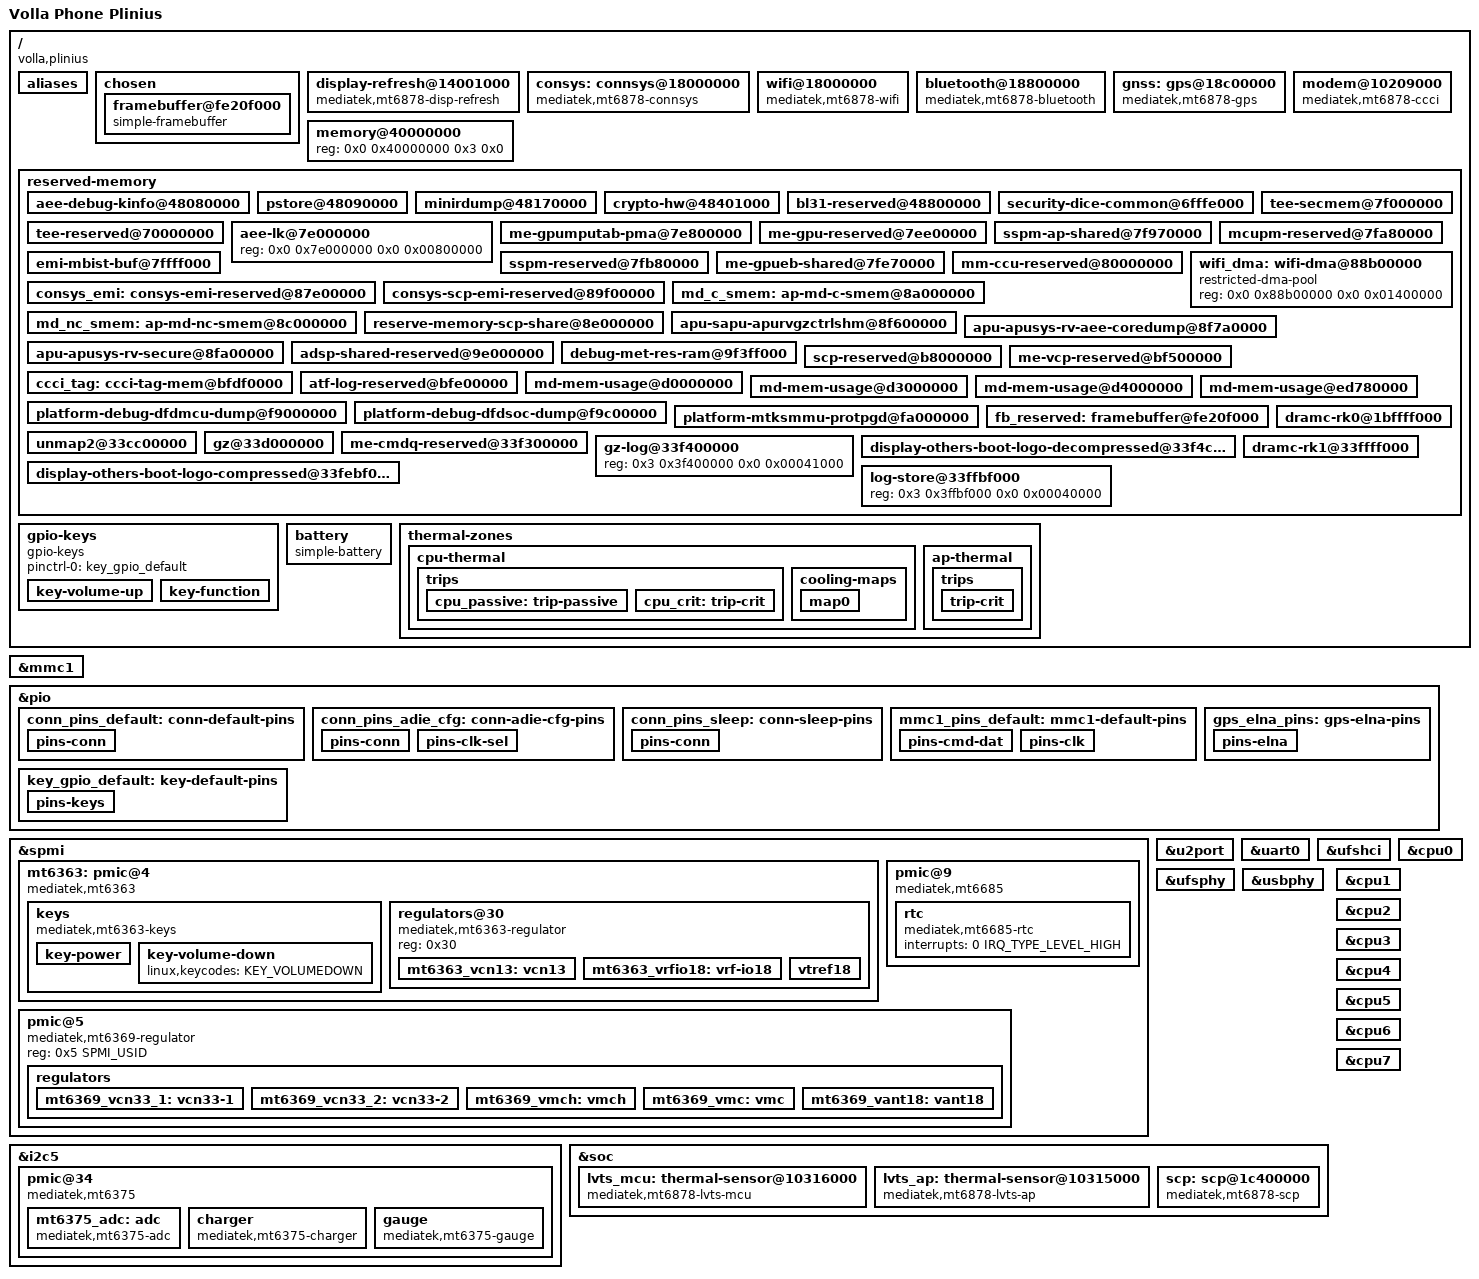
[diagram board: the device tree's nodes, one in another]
// SPDX-License-Identifier: GPL-2.0 OR MIT
/*
 * Volla Phone Plinius (ansuz)
 */

/dts-v1/;
#include "mt6878.dtsi"
#include <dt-bindings/gpio/gpio.h>
#include <dt-bindings/iio/adc/mediatek,mt6375_adc.h>
#include <dt-bindings/input/input.h>
#include <dt-bindings/interrupt-controller/irq.h>
#include <dt-bindings/mfd/mt6375.h>
#include <dt-bindings/pinctrl/mt65xx.h>
#include <dt-bindings/power/mediatek,mt6878-power.h>
#include <dt-bindings/spmi/spmi.h>
#include <dt-bindings/thermal/mediatek,lvts-thermal.h>
#include <dt-bindings/thermal/thermal.h>

/*
 * The SoC dtsi carries the CMF Phone 1 carveouts, Plinius gets its own
 * set taken from what the stock LK hands to the kernel.
 */
/delete-node/ &{/reserved-memory};

/ {
	model = "Volla Phone Plinius";
	chassis-type = "handset";
	compatible = "volla,plinius", "mediatek,mt6878";

	#address-cells = <2>;
	#size-cells = <2>;

	aliases {
		mmc1 = &mmc1;
		serial0 = &uart0;
	};

	chosen {
		bootargs = "clk_ignore_unused";
		stdout-path = "serial0:921600n8";
		#address-cells = <2>;
		#size-cells = <2>;
		ranges;

		/* Left set up by the stock LK */
		framebuffer@fe20f000 {
			compatible = "simple-framebuffer";
			reg = <0x0 0xfe20f000 0x0 0xa08c00>;
			memory-region = <&fb_reserved>;
			width = <1080>;
			height = <2400>;
			stride = <(1088 * 4)>;
			format = "a8r8g8b8";
		};
	};

	/*
	 * The LK leaves OVL0 -> ... -> DSI0 scanning out the framebuffer
	 * above to the command mode panel; keep pushing frames to it.
	 */
	display-refresh@14001000 {
		compatible = "mediatek,mt6878-disp-refresh";
		reg = <0x0 0x14001000 0x0 0x1000>,
		      <0x0 0x1401a000 0x0 0x1000>;
		reg-names = "mutex", "dsi";
		mediatek,mutex-id = <0>;
	};

	/* Connectivity subsystem (WiFi/BT/GPS) with the MT6637 A-die */
	consys: connsys@18000000 {
		compatible = "mediatek,mt6878-connsys";
		reg = <0x0 0x18000000 0x0 0x80000>,
		      <0x0 0x1c00d000 0x0 0x1000>;
		reg-names = "conn", "srclken-rc";
		memory-region = <&consys_emi>;
		power-domains = <&spm MT6878_POWER_DOMAIN_CONN>;
		mediatek,topckgen = <&topckgen>;
		pinctrl-names = "default", "sleep", "adie-cfg";
		pinctrl-0 = <&conn_pins_default>;
		pinctrl-1 = <&conn_pins_sleep>;
		pinctrl-2 = <&conn_pins_adie_cfg>;
		vrfio18-supply = <&mt6363_vrfio18>;
		vcn13-supply = <&mt6363_vcn13>;
		vcn33-1-supply = <&mt6369_vcn33_1>;
		vcn33-2-supply = <&mt6369_vcn33_2>;
		vant18-supply = <&mt6369_vant18>;
	};

	wifi@18000000 {
		compatible = "mediatek,mt6878-wifi";
		reg = <0x0 0x18000000 0x0 0x700000>;
		interrupts = <GIC_SPI 484 IRQ_TYPE_LEVEL_HIGH 0>,
			     <GIC_SPI 692 IRQ_TYPE_LEVEL_HIGH 0>;
		memory-region = <&wifi_dma>;
		mediatek,connsys = <&consys>;
	};

	bluetooth@18800000 {
		compatible = "mediatek,mt6878-bluetooth";
		reg = <0x0 0x18000000 0x0 0x61000>,
		      <0x0 0x18800000 0x0 0x21000>;
		reg-names = "conn", "bgf";
		interrupts = <GIC_SPI 693 IRQ_TYPE_LEVEL_HIGH 0>;
		mediatek,connsys = <&consys>;
		/* Factory BD address 58:9E:C6:AB:A6:1A (little-endian here) */
		local-bd-address = [1a a6 ab c6 9e 58];
	};

	gnss: gps@18c00000 {
		compatible = "mediatek,mt6878-gps";
		reg = <0x0 0x18c00000 0x0 0x100000>,
		      <0x0 0x18000000 0x0 0x100000>;
		reg-names = "conn_gps", "conn_infra";
		/* link0 data, link0 nodata, link0 mcub, link1 data,
		 * link1 nodata, link1 mcub, dma (index order matters)
		 */
		interrupts = <GIC_SPI 379 IRQ_TYPE_LEVEL_HIGH 0>,
			     <GIC_SPI 380 IRQ_TYPE_LEVEL_HIGH 0>,
			     <GIC_SPI 381 IRQ_TYPE_LEVEL_HIGH 0>,
			     <GIC_SPI 382 IRQ_TYPE_LEVEL_HIGH 0>,
			     <GIC_SPI 383 IRQ_TYPE_LEVEL_HIGH 0>,
			     <GIC_SPI 389 IRQ_TYPE_LEVEL_HIGH 0>,
			     <GIC_SPI 129 IRQ_TYPE_LEVEL_HIGH 0>;
		mediatek,connsys = <&consys>;
		/*
		 * GPIO186/187 = external GPS L1/L5 eLNA enable. Stock drives them
		 * from its "gps_l1_lna_enable"/"gps_l5_lna_enable" pinctrl states;
		 * mainline left them unclaimed so the eLNAs stayed off and the DSP
		 * saw few/no satellites. Claim them as GPIO outputs driven high for
		 * the whole time the GPS device is bound.
		 */
		pinctrl-names = "default";
		pinctrl-0 = <&gps_elna_pins>;
	};

	modem@10209000 {
		compatible = "mediatek,mt6878-ccci";
		reg = <0x0 0x10209000 0x0 0x1000>,
		      <0x0 0x1020a000 0x0 0x1000>,
		      <0x0 0x1020e000 0x0 0x1000>,
		      <0x0 0x1c001000 0x0 0x1000>,
		      <0x0 0x10000000 0x0 0x1000>,
		      <0x0 0x10001000 0x0 0x1000>,
		      <0x0 0x10270000 0x0 0x1000>,
		      <0x0 0x10014000 0x0 0x1000>,
		      <0x0 0x1022d000 0x0 0x1000>;
		reg-names = "ap-ccif", "md-ccif", "infracfg", "spm", "topckgen",
			    "infracfg-ao", "nemicfg", "dpmaif-ao", "dpmaif-pd";
		interrupts = <GIC_SPI 228 IRQ_TYPE_LEVEL_HIGH 0>,
			     <GIC_SPI 229 IRQ_TYPE_LEVEL_HIGH 0>,
			     <GIC_SPI 238 IRQ_TYPE_LEVEL_HIGH 0>;
		memory-region = <&ccci_tag>, <&md_nc_smem>, <&md_c_smem>;
	};

	memory@40000000 {
		device_type = "memory";
		reg = <0x0 0x40000000 0x3 0x0>;
	};

	reserved-memory {
		#address-cells = <2>;
		#size-cells = <2>;
		ranges;

		aee-debug-kinfo@48080000 {
			reg = <0x0 0x48080000 0x0 0x00010000>;
			no-map;
		};

		pstore@48090000 {
			reg = <0x0 0x48090000 0x0 0x000e0000>;
			no-map;
		};

		minirdump@48170000 {
			reg = <0x0 0x48170000 0x0 0x00010000>;
			no-map;
		};

		crypto-hw@48401000 {
			reg = <0x0 0x48401000 0x0 0x00001000>;
			no-map;
		};

		bl31-reserved@48800000 {
			reg = <0x0 0x48800000 0x0 0x00200000>;
			no-map;
		};

		security-dice-common@6fffe000 {
			reg = <0x0 0x6fffe000 0x0 0x00001000>;
			no-map;
		};

		tee-reserved@70000000 {
			reg = <0x0 0x70000000 0x0 0x06c00000>;
			no-map;
		};

		aee-lk@7e000000 {
			reg = <0x0 0x7e000000 0x0 0x00800000>;
		};

		me-gpumputab-pma@7e800000 {
			reg = <0x0 0x7e800000 0x0 0x00600000>;
			no-map;
		};

		me-gpu-reserved@7ee00000 {
			reg = <0x0 0x7ee00000 0x0 0x00200000>;
			no-map;
		};

		tee-secmem@7f000000 {
			reg = <0x0 0x7f000000 0x0 0x00900000>;
			no-map;
		};

		sspm-ap-shared@7f970000 {
			reg = <0x0 0x7f970000 0x0 0x00110000>;
			no-map;
		};

		mcupm-reserved@7fa80000 {
			reg = <0x0 0x7fa80000 0x0 0x00100000>;
			no-map;
		};

		sspm-reserved@7fb80000 {
			reg = <0x0 0x7fb80000 0x0 0x00280000>;
			no-map;
		};

		me-gpueb-shared@7fe70000 {
			reg = <0x0 0x7fe70000 0x0 0x00180000>;
			no-map;
		};

		emi-mbist-buf@7ffff000 {
			reg = <0x0 0x7ffff000 0x0 0x00001000>;
			no-map;
		};

		mm-ccu-reserved@80000000 {
			reg = <0x0 0x80000000 0x0 0x00100000>;
			no-map;
		};

		consys_emi: consys-emi-reserved@87e00000 {
			reg = <0x0 0x87e00000 0x0 0x00d00000>;
			no-map;
		};

		/* The connsys may only access the memory the bootloader allows it */
		wifi_dma: wifi-dma@88b00000 {
			compatible = "restricted-dma-pool";
			reg = <0x0 0x88b00000 0x0 0x01400000>;
		};

		consys-scp-emi-reserved@89f00000 {
			reg = <0x0 0x89f00000 0x0 0x00020000>;
			no-map;
		};

		md_c_smem: ap-md-c-smem@8a000000 {
			reg = <0x0 0x8a000000 0x0 0x01960000>;
			no-map;
		};

		md_nc_smem: ap-md-nc-smem@8c000000 {
			reg = <0x0 0x8c000000 0x0 0x00130000>;
			no-map;
		};

		reserve-memory-scp-share@8e000000 {
			reg = <0x0 0x8e000000 0x0 0x011c8000>;
			no-map;
		};

		apu-sapu-apurvgzctrlshm@8f600000 {
			reg = <0x0 0x8f600000 0x0 0x00100000>;
			no-map;
		};

		apu-apusys-rv-aee-coredump@8f7a0000 {
			reg = <0x0 0x8f7a0000 0x0 0x00260000>;
			no-map;
		};

		apu-apusys-rv-secure@8fa00000 {
			reg = <0x0 0x8fa00000 0x0 0x00600000>;
			no-map;
		};

		adsp-shared-reserved@9e000000 {
			reg = <0x0 0x9e000000 0x0 0x00b60000>;
			no-map;
		};

		debug-met-res-ram@9f3ff000 {
			reg = <0x0 0x9f3ff000 0x0 0x00c00000>;
			no-map;
		};

		scp-reserved@b8000000 {
			reg = <0x0 0xb8000000 0x0 0x02300000>;
			no-map;
		};

		me-vcp-reserved@bf500000 {
			reg = <0x0 0xbf500000 0x0 0x00800000>;
			no-map;
		};

		ccci_tag: ccci-tag-mem@bfdf0000 {
			reg = <0x0 0xbfdf0000 0x0 0x00010000>;
			no-map;
		};

		atf-log-reserved@bfe00000 {
			reg = <0x0 0xbfe00000 0x0 0x00200000>;
			no-map;
		};

		md-mem-usage@d0000000 {
			reg = <0x0 0xd0000000 0x0 0x029a0000>;
			no-map;
		};

		md-mem-usage@d3000000 {
			reg = <0x0 0xd3000000 0x0 0x00250000>;
			no-map;
		};

		md-mem-usage@d4000000 {
			reg = <0x0 0xd4000000 0x0 0x06df0000>;
			no-map;
		};

		md-mem-usage@ed780000 {
			reg = <0x0 0xed780000 0x0 0x00880000>;
			no-map;
		};

		platform-debug-dfdmcu-dump@f9000000 {
			reg = <0x0 0xf9000000 0x0 0x00100000>;
			no-map;
		};

		platform-debug-dfdsoc-dump@f9c00000 {
			reg = <0x0 0xf9c00000 0x0 0x00200000>;
			no-map;
		};

		platform-mtksmmu-protpgd@fa000000 {
			reg = <0x0 0xfa000000 0x0 0x04200000>;
			no-map;
		};

		fb_reserved: framebuffer@fe20f000 {
			reg = <0x0 0xfe20f000 0x0 0x01df0000>;
			no-map;
		};

		dramc-rk0@1bffff000 {
			reg = <0x1 0xbffff000 0x0 0x00001000>;
			no-map;
		};

		unmap2@33cc00000 {
			reg = <0x3 0x3cc00000 0x0 0x00200000>;
			no-map;
		};

		gz@33d000000 {
			reg = <0x3 0x3d000000 0x0 0x02200000>;
			no-map;
		};

		me-cmdq-reserved@33f300000 {
			reg = <0x3 0x3f300000 0x0 0x00100000>;
			no-map;
		};

		gz-log@33f400000 {
			reg = <0x3 0x3f400000 0x0 0x00041000>;
		};

		display-others-boot-logo-decompressed@33f4c9000 {
			reg = <0x3 0x3f4c9000 0x0 0x009f6000>;
			no-map;
		};

		display-others-boot-logo-compressed@33febf000 {
			reg = <0x3 0x3febf000 0x0 0x00100000>;
			no-map;
		};

		log-store@33ffbf000 {
			reg = <0x3 0x3ffbf000 0x0 0x00040000>;
		};

		dramc-rk1@33ffff000 {
			reg = <0x3 0x3ffff000 0x0 0x00001000>;
			no-map;
		};
	};

	gpio-keys {
		compatible = "gpio-keys";

		pinctrl-0 = <&key_gpio_default>;
		pinctrl-names = "default";

		key-volume-up {
			label = "Volume Up";
			linux,code = <KEY_VOLUMEUP>;
			gpios = <&pio 54 GPIO_ACTIVE_LOW>;
			debounce-interval = <30>;
			wakeup-source;
		};

		key-function {
			label = "Function";
			linux,code = <KEY_PROG1>;
			gpios = <&pio 55 GPIO_ACTIVE_LOW>;
			debounce-interval = <30>;
			wakeup-source;
		};
	};
};

&mmc1 {
	pinctrl-names = "default", "state_uhs";
	pinctrl-0 = <&mmc1_pins_default>;
	pinctrl-1 = <&mmc1_pins_default>;
	bus-width = <4>;
	max-frequency = <200000000>;
	cap-sd-highspeed;
	sd-uhs-sdr12;
	sd-uhs-sdr25;
	sd-uhs-sdr50;
	sd-uhs-sdr104;
	sd-uhs-ddr50;
	cd-gpios = <&pio 14 GPIO_ACTIVE_LOW>;
	vmmc-supply = <&mt6369_vmch>;
	vqmmc-supply = <&mt6369_vmc>;
	no-mmc;
	no-sdio;
	status = "okay";
};

&pio {
	conn_pins_default: conn-default-pins {
		pins-conn {
			pinmux = <PINMUX_GPIO172__FUNC_CONN_TOP_CLK>,
				 <PINMUX_GPIO173__FUNC_CONN_TOP_DATA>,
				 <PINMUX_GPIO174__FUNC_CONN_BT_CLK>,
				 <PINMUX_GPIO175__FUNC_CONN_BT_DATA>,
				 <PINMUX_GPIO176__FUNC_CONN_HRST_B>,
				 <PINMUX_GPIO177__FUNC_CONN_WB_PTA>,
				 <PINMUX_GPIO178__FUNC_CONN_WF_CTRL0>,
				 <PINMUX_GPIO179__FUNC_CONN_WF_CTRL1>,
				 <PINMUX_GPIO180__FUNC_CONN_WF_CTRL2>,
				 <PINMUX_GPIO181__FUNC_CONN_WF_CTRL3>,
				 <PINMUX_GPIO182__FUNC_CONN_WF_CTRL4>;
			drive-strength = <4>;
		};
	};

	/* CONN_WF_CTRL2 low selects a 26 MHz clock while the A-die is set up */
	conn_pins_adie_cfg: conn-adie-cfg-pins {
		pins-conn {
			pinmux = <PINMUX_GPIO172__FUNC_CONN_TOP_CLK>,
				 <PINMUX_GPIO173__FUNC_CONN_TOP_DATA>,
				 <PINMUX_GPIO174__FUNC_CONN_BT_CLK>,
				 <PINMUX_GPIO175__FUNC_CONN_BT_DATA>,
				 <PINMUX_GPIO176__FUNC_CONN_HRST_B>,
				 <PINMUX_GPIO177__FUNC_CONN_WB_PTA>,
				 <PINMUX_GPIO178__FUNC_CONN_WF_CTRL0>,
				 <PINMUX_GPIO179__FUNC_CONN_WF_CTRL1>,
				 <PINMUX_GPIO181__FUNC_CONN_WF_CTRL3>,
				 <PINMUX_GPIO182__FUNC_CONN_WF_CTRL4>;
			drive-strength = <4>;
		};

		pins-clk-sel {
			pinmux = <PINMUX_GPIO180__FUNC_GPIO180>;
			output-low;
		};
	};

	conn_pins_sleep: conn-sleep-pins {
		pins-conn {
			pinmux = <PINMUX_GPIO172__FUNC_GPIO172>,
				 <PINMUX_GPIO173__FUNC_GPIO173>,
				 <PINMUX_GPIO174__FUNC_GPIO174>,
				 <PINMUX_GPIO175__FUNC_GPIO175>,
				 <PINMUX_GPIO176__FUNC_GPIO176>,
				 <PINMUX_GPIO177__FUNC_GPIO177>,
				 <PINMUX_GPIO178__FUNC_GPIO178>,
				 <PINMUX_GPIO179__FUNC_GPIO179>,
				 <PINMUX_GPIO180__FUNC_GPIO180>,
				 <PINMUX_GPIO181__FUNC_GPIO181>,
				 <PINMUX_GPIO182__FUNC_GPIO182>;
		};
	};

	mmc1_pins_default: mmc1-default-pins {
		pins-cmd-dat {
			pinmux = <PINMUX_GPIO78__FUNC_MSDC1_CMD>,
				 <PINMUX_GPIO79__FUNC_MSDC1_DAT0>,
				 <PINMUX_GPIO80__FUNC_MSDC1_DAT1>,
				 <PINMUX_GPIO81__FUNC_MSDC1_DAT2>,
				 <PINMUX_GPIO82__FUNC_MSDC1_DAT3>;
			input-enable;
			drive-strength = <8>;
			bias-pull-up = <MTK_PUPD_SET_R1R0_01>;
		};

		pins-clk {
			pinmux = <PINMUX_GPIO77__FUNC_MSDC1_CLK>;
			drive-strength = <8>;
			bias-pull-down = <MTK_PUPD_SET_R1R0_10>;
		};
	};

	key_gpio_default: key-default-pins {
		pins-keys {
			pinmux = <PINMUX_GPIO54__FUNC_GPIO54>,
				 <PINMUX_GPIO55__FUNC_GPIO55>;
			input-enable;
			bias-pull-up;
		};
	};

	/* External GPS L1/L5 eLNA enable, held high while GPS is bound */
	gps_elna_pins: gps-elna-pins {
		pins-elna {
			pinmux = <PINMUX_GPIO186__FUNC_GPIO186>,
				 <PINMUX_GPIO187__FUNC_GPIO187>;
			output-high;
		};
	};
};

&spmi {
	status = "okay";

	mt6363: pmic@4 {
		compatible = "mediatek,mt6363";
		reg = <0x4 SPMI_USID>;
		interrupts = <4 64 IRQ_TYPE_LEVEL_HIGH>;
		interrupt-controller;
		#interrupt-cells = <3>;
		#address-cells = <1>;
		#size-cells = <0>;

		keys {
			compatible = "mediatek,mt6363-keys";
			interrupts = <4 48 IRQ_TYPE_LEVEL_HIGH>,
				     <4 51 IRQ_TYPE_LEVEL_HIGH>,
				     <4 49 IRQ_TYPE_LEVEL_HIGH>,
				     <4 52 IRQ_TYPE_LEVEL_HIGH>;
			interrupt-names = "powerkey", "powerkey_r",
					  "homekey", "homekey_r";

			key-power {
				linux,keycodes = <KEY_POWER>;
				wakeup-source;
			};

			key-volume-down {
				linux,keycodes = <KEY_VOLUMEDOWN>;
			};
		};

		regulators@30 {
			compatible = "mediatek,mt6363-regulator";
			reg = <0x30>;

			mt6363_vcn13: vcn13 {
				regulator-name = "mt6363_vcn13";
				regulator-min-microvolt = <1300000>;
				regulator-max-microvolt = <1300000>;
			};

			mt6363_vrfio18: vrf-io18 {
				regulator-name = "mt6363_vrfio18";
				regulator-min-microvolt = <1800000>;
				regulator-max-microvolt = <1800000>;
			};

			/* RF reference supply of the modem, always on in stock */
			vtref18 {
				regulator-name = "mt6363_vtref18";
				regulator-min-microvolt = <1800000>;
				regulator-max-microvolt = <1800000>;
				regulator-always-on;
			};
		};
	};

	pmic@9 {
		compatible = "mediatek,mt6685";
		reg = <0x9 SPMI_USID>;
		interrupts = <9 0 IRQ_TYPE_LEVEL_HIGH>;
		interrupt-controller;
		#interrupt-cells = <2>;

		rtc {
			compatible = "mediatek,mt6685-rtc";
			interrupts = <0 IRQ_TYPE_LEVEL_HIGH>;
		};
	};

	pmic@5 {
		compatible = "mediatek,mt6369-regulator";
		reg = <0x5 SPMI_USID>;

		regulators {
			mt6369_vcn33_1: vcn33-1 {
				regulator-name = "mt6369_vcn33_1";
				regulator-min-microvolt = <3300000>;
				regulator-max-microvolt = <3500000>;
			};

			mt6369_vcn33_2: vcn33-2 {
				regulator-name = "mt6369_vcn33_2";
				regulator-min-microvolt = <3300000>;
				regulator-max-microvolt = <3300000>;
			};

			mt6369_vmch: vmch {
				regulator-name = "mt6369_vmch";
				regulator-min-microvolt = <2900000>;
				regulator-max-microvolt = <2900000>;
			};

			mt6369_vmc: vmc {
				regulator-name = "mt6369_vmc";
				regulator-min-microvolt = <1800000>;
				regulator-max-microvolt = <3300000>;
			};

			mt6369_vant18: vant18 {
				regulator-name = "mt6369_vant18";
				regulator-min-microvolt = <1800000>;
				regulator-max-microvolt = <1800000>;
			};
		};
	};
};

&u2port {
	status = "okay";
};

&uart0 {
	status = "okay";
};

&ufshci {
	status = "okay";
};

&ufsphy {
	status = "okay";
};

&usbphy {
	status = "okay";
};

&i2c5 {
	status = "okay";

	pmic@34 {
		compatible = "mediatek,mt6375";
		reg = <0x34>;
		interrupts-extended = <&pio 15 IRQ_TYPE_LEVEL_LOW>;
		interrupt-controller;
		#interrupt-cells = <1>;

		mt6375_adc: adc {
			compatible = "mediatek,mt6375-adc";
			#io-channel-cells = <1>;
		};

		charger {
			compatible = "mediatek,mt6375-charger";
			interrupts = <MT6375_FL_PWR_RDY>,
				     <MT6375_FL_DETACH>,
				     <MT6375_FL_BC12_DN>;
			interrupt-names = "attach", "detach", "bc12_done";
		};

		gauge {
			compatible = "mediatek,mt6375-gauge";
			io-channels = <&mt6375_adc MT6375_ADC_VBAT>,
				      <&mt6375_adc MT6375_ADC_IBAT>;
			io-channel-names = "vbat", "ibat";
			monitored-battery = <&battery>;
		};
	};
};

/ {
	/*
	 * Open-circuit-voltage / capacity table derived from the stock
	 * battery0-profile-t1 (25 degC) OCV curve; charge-full-design taken
	 * from the same profile's Qmax.
	 */
	battery: battery {
		compatible = "simple-battery";
		device-chemistry = "lithium-ion";
		charge-full-design-microamp-hours = <3022000>;
		voltage-max-design-microvolt = <4322000>;
		voltage-min-design-microvolt = <3400000>;
		factory-internal-resistance-micro-ohms = <120000>;
		ocv-capacity-celsius = <25>;
		ocv-capacity-table-0 = <4322000 100>, <4259456 95>,
			<4201235 90>, <4147838 85>, <4095360 80>,
			<4051790 75>, <3996275 70>, <3963626 65>,
			<3914300 60>, <3867020 55>, <3840800 50>,
			<3819158 45>, <3801540 40>, <3789828 35>,
			<3774667 30>, <3755678 25>, <3738580 20>,
			<3710409 15>, <3691199 10>, <3619774 5>,
			<3400000 0>;
	};
};

&soc {
	lvts_mcu: thermal-sensor@10316000 {
		compatible = "mediatek,mt6878-lvts-mcu";
		reg = <0x10316000 0x1000>;
		interrupts = <GIC_SPI 219 IRQ_TYPE_LEVEL_HIGH 0>;
		#thermal-sensor-cells = <1>;
	};

	lvts_ap: thermal-sensor@10315000 {
		compatible = "mediatek,mt6878-lvts-ap";
		reg = <0x10315000 0x1000>;
		interrupts = <GIC_SPI 218 IRQ_TYPE_LEVEL_HIGH 0>;
		#thermal-sensor-cells = <1>;
	};

	scp: scp@1c400000 {
		compatible = "mediatek,mt6878-scp";
		reg = <0x1c400000 0x100000>,
		      <0x1cb24000 0x1000>,
		      <0x1cb30000 0x1000>,
		      <0x1cb40000 0x1000>,
		      <0x1cba0000 0x1000>,
		      <0x1cbb0000 0x1000>,
		      <0x1cbc0000 0x1000>,
		      <0x1cbd0000 0x1000>,
		      <0x1cbe0000 0x1000>;
		reg-names = "sram", "cfg", "cfg_core0", "cfg_core1",
			    "mbox0", "mbox1", "mbox2", "mbox3", "mbox4";
		interrupts = <GIC_SPI 516 IRQ_TYPE_LEVEL_HIGH 0>,
			     <GIC_SPI 517 IRQ_TYPE_LEVEL_HIGH 0>,
			     <GIC_SPI 518 IRQ_TYPE_LEVEL_HIGH 0>,
			     <GIC_SPI 519 IRQ_TYPE_LEVEL_HIGH 0>,
			     <GIC_SPI 520 IRQ_TYPE_LEVEL_HIGH 0>,
			     <GIC_SPI 521 IRQ_TYPE_LEVEL_HIGH 0>,
			     <GIC_SPI 522 IRQ_TYPE_LEVEL_HIGH 0>;
		interrupt-names = "ipc0", "ipc1", "mbox0", "mbox1",
				  "mbox2", "mbox3", "mbox4";
		mediatek,infracfg = <&infracfg_ao>;
	};
};

&cpu0 { #cooling-cells = <2>; };
&cpu1 { #cooling-cells = <2>; };
&cpu2 { #cooling-cells = <2>; };
&cpu3 { #cooling-cells = <2>; };
&cpu4 { #cooling-cells = <2>; };
&cpu5 { #cooling-cells = <2>; };
&cpu6 { #cooling-cells = <2>; };
&cpu7 { #cooling-cells = <2>; };

/ {
	thermal-zones {
		cpu-thermal {
			polling-delay = <1000>;
			polling-delay-passive = <250>;
			thermal-sensors = <&lvts_mcu MT6878_MCU_LVTS1_0>;

			trips {
				cpu_passive: trip-passive {
					temperature = <85000>;
					hysteresis = <2000>;
					type = "passive";
				};

				cpu_crit: trip-crit {
					temperature = <115000>;
					hysteresis = <1000>;
					type = "critical";
				};
			};

			cooling-maps {
				map0 {
					trip = <&cpu_passive>;
					cooling-device =
						<&cpu0 THERMAL_NO_LIMIT THERMAL_NO_LIMIT>,
						<&cpu1 THERMAL_NO_LIMIT THERMAL_NO_LIMIT>,
						<&cpu2 THERMAL_NO_LIMIT THERMAL_NO_LIMIT>,
						<&cpu3 THERMAL_NO_LIMIT THERMAL_NO_LIMIT>,
						<&cpu4 THERMAL_NO_LIMIT THERMAL_NO_LIMIT>,
						<&cpu5 THERMAL_NO_LIMIT THERMAL_NO_LIMIT>,
						<&cpu6 THERMAL_NO_LIMIT THERMAL_NO_LIMIT>,
						<&cpu7 THERMAL_NO_LIMIT THERMAL_NO_LIMIT>;
				};
			};
		};

		ap-thermal {
			polling-delay = <1000>;
			polling-delay-passive = <0>;
			thermal-sensors = <&lvts_ap MT6878_AP_LVTS5_0>;

			trips {
				trip-crit {
					temperature = <115000>;
					hysteresis = <1000>;
					type = "critical";
				};
			};
		};
	};
};
